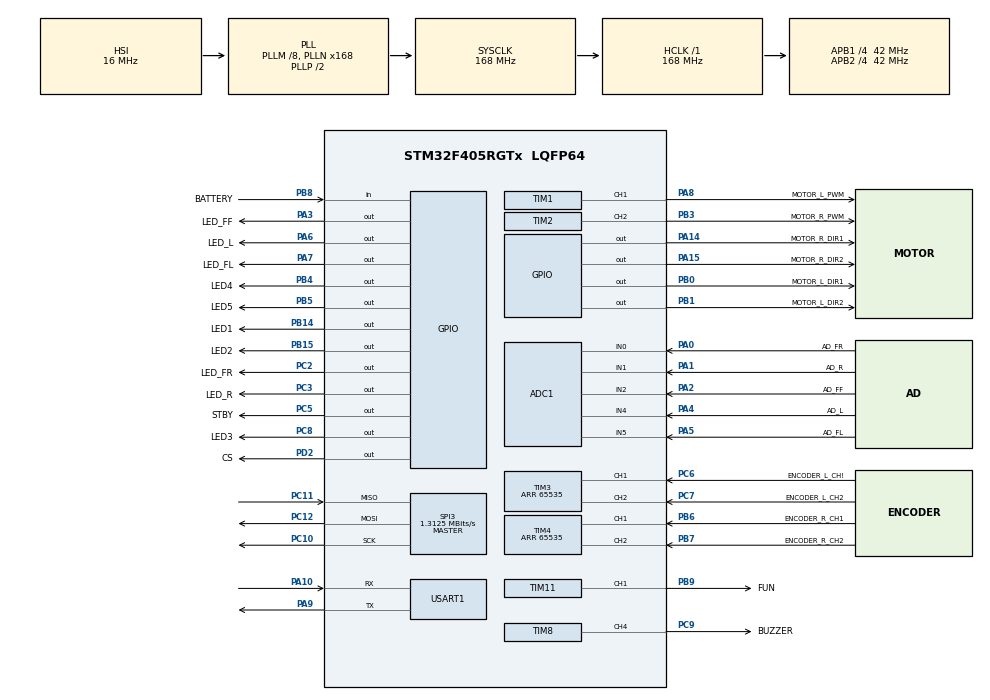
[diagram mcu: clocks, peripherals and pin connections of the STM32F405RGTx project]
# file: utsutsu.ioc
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ADC1.Channel-0\#ChannelRegularConversion=ADC_CHANNEL_0
ADC1.ContinuousConvMode=DISABLE
ADC1.DMAContinuousRequests=DISABLE
ADC1.DiscontinuousConvMode=DISABLE
ADC1.InjNumberOfConversion=0
ADC1.NbrOfConversion=1
ADC1.NbrOfConversionFlag=1
ADC1.Rank-0\#ChannelRegularConversion=1
ADC1.SamplingTime-0\#ChannelRegularConversion=ADC_SAMPLETIME_3CYCLES
ADC1.master=1
Mcu.Family=STM32F4
Mcu.Name=STM32F405RGTx
Mcu.Package=LQFP64
NVIC.PriorityGroup=NVIC_PRIORITYGROUP_4
NVIC.TIM1_BRK_TIM9_IRQn=true\:1\:0\:true\:false\:true\:true\:true
NVIC.TIM2_IRQn=true\:2\:0\:true\:false\:true\:true\:true
NVIC.TIM6_DAC_IRQn=true\:3\:0\:true\:false\:true\:true\:true
PA0-WKUP.GPIO_Label=AD_FR
PA0-WKUP.Signal=ADCx_IN0
PA1.GPIO_Label=AD_R
PA1.Signal=ADCx_IN1
PA10.Mode=Asynchronous
PA10.Signal=USART1_RX
PA14.GPIO_Label=MOTOR_R_DIR1
PA14.Signal=GPIO_Output
PA15.GPIO_Label=MOTOR_R_DIR2
PA15.Signal=GPIO_Output
PA2.GPIO_Label=AD_FF
PA2.Signal=ADCx_IN2
PA3.GPIO_Label=LED_FF
PA3.Signal=GPIO_Output
PA4.GPIO_Label=AD_L
PA4.Signal=ADCx_IN4
PA5.GPIO_Label=AD_FL
PA5.Signal=ADCx_IN5
PA6.GPIO_Label=LED_L
PA6.Signal=GPIO_Output
PA7.GPIO_Label=LED_FL
PA7.Signal=GPIO_Output
PA8.GPIO_Label=MOTOR_L_PWM
PA8.Signal=S_TIM1_CH1
PA9.Mode=Asynchronous
PA9.Signal=USART1_TX
PB0.GPIO_Label=MOTOR_L_DIR1
PB0.Signal=GPIO_Output
PB1.GPIO_Label=MOTOR_L_DIR2
PB1.Signal=GPIO_Output
PB14.GPIO_Label=LED1
PB14.Signal=GPIO_Output
PB15.GPIO_Label=LED2
PB15.Signal=GPIO_Output
PB3.GPIO_Label=MOTOR_R_PWM
PB3.Signal=S_TIM2_CH2
PB4.GPIO_Label=LED4
PB4.Signal=GPIO_Output
PB5.GPIO_Label=LED5
PB5.Signal=GPIO_Output
PB6.GPIO_Label=ENCODER_R_CH1
PB6.Signal=S_TIM4_CH1
PB7.GPIO_Label=ENCODER_R_CH2
PB7.Signal=S_TIM4_CH2
PB8.GPIO_Label=BATTERY
PB8.GPIO_PuPd=GPIO_PULLUP
PB8.Signal=GPIO_Input
PB9.GPIO_Label=FUN
PB9.Signal=S_TIM11_CH1
PC10.Mode=Full_Duplex_Master
PC10.Signal=SPI3_SCK
PC11.Mode=Full_Duplex_Master
PC11.Signal=SPI3_MISO
PC12.Mode=Full_Duplex_Master
PC12.Signal=SPI3_MOSI
PC2.GPIO_Label=LED_FR
PC2.Signal=GPIO_Output
PC3.GPIO_Label=LED_R
PC3.Signal=GPIO_Output
PC5.GPIO_Label=STBY
PC5.Signal=GPIO_Output
PC6.GPIO_Label=ENCODER_L_CH\!
PC6.Signal=S_TIM3_CH1
PC7.GPIO_Label=ENCODER_L_CH2
PC7.Signal=S_TIM3_CH2
PC8.GPIO_Label=LED3
PC8.Signal=GPIO_Output
PC9.GPIO_Label=BUZZER
PC9.Signal=S_TIM8_CH4
PD2.GPIO_Label=CS
PD2.Signal=GPIO_Output
ProjectManager.HeapSize=0x200
ProjectManager.StackSize=0x400
ProjectManager.TargetToolchain=STM32CubeIDE
RCC.48MHZClocksFreq_Value=84000000
RCC.AHBFreq_Value=168000000
RCC.APB1CLKDivider=RCC_HCLK_DIV4
RCC.APB1Freq_Value=42000000
RCC.APB1TimFreq_Value=84000000
RCC.APB2CLKDivider=RCC_HCLK_DIV4
RCC.APB2Freq_Value=42000000
RCC.APB2TimFreq_Value=84000000
RCC.CortexFreq_Value=168000000
RCC.HCLKFreq_Value=168000000
RCC.HSE_VALUE=25000000
RCC.HSI_VALUE=16000000
RCC.LSE_VALUE=32768
RCC.PLLM=8
RCC.PLLN=168
RCC.SYSCLKFreq_VALUE=168000000
RCC.SYSCLKSource=RCC_SYSCLKSOURCE_PLLCLK
RCC.VCOOutputFreq_Value=336000000
SH.ADCx_IN0.0=ADC1_IN0,IN0
SH.ADCx_IN1.0=ADC1_IN1,IN1
SH.ADCx_IN2.0=ADC1_IN2,IN2
SH.ADCx_IN4.0=ADC1_IN4,IN4
SH.ADCx_IN5.0=ADC1_IN5,IN5
SH.S_TIM11_CH1.0=TIM11_CH1,PWM Generation1 CH1
SH.S_TIM1_CH1.0=TIM1_CH1,PWM Generation1 CH1
SH.S_TIM2_CH2.0=TIM2_CH2,PWM Generation2 CH2
SH.S_TIM3_CH1.0=TIM3_CH1,Encoder_Interface
SH.S_TIM3_CH2.0=TIM3_CH2,Encoder_Interface
SH.S_TIM4_CH1.0=TIM4_CH1,Encoder_Interface
SH.S_TIM4_CH2.0=TIM4_CH2,Encoder_Interface
SH.S_TIM8_CH4.0=TIM8_CH4,PWM Generation4 CH4
SPI3.BaudRatePrescaler=SPI_BAUDRATEPRESCALER_32
SPI3.CLKPhase=SPI_PHASE_2EDGE
SPI3.CLKPolarity=SPI_POLARITY_HIGH
SPI3.CalculateBaudRate=1.3125 MBits/s
SPI3.Direction=SPI_DIRECTION_2LINES
SPI3.Mode=SPI_MODE_MASTER
SPI3.VirtualType=VM_MASTER
TIM1.Channel-PWM\ Generation1\ CH1=TIM_CHANNEL_1
TIM1.OCPolarity_1=TIM_OCPOLARITY_HIGH
TIM1.Period=1000
TIM1.Pulse-PWM\ Generation1\ CH1=500
TIM11.Channel=TIM_CHANNEL_1
TIM11.Period=1000
TIM2.Channel-PWM\ Generation2\ CH2=TIM_CHANNEL_2
TIM2.OCMode_PWM-PWM\ Generation2\ CH2=TIM_OCMODE_PWM1
TIM2.OCPolarity_2=TIM_OCPOLARITY_HIGH
TIM2.Period=1000
TIM2.Pulse-PWM\ Generation2\ CH2=500
TIM3.EncoderMode=TIM_ENCODERMODE_TI12
TIM3.Period=65535
TIM4.EncoderMode=TIM_ENCODERMODE_TI12
TIM4.Period=65535
TIM6.AutoReloadPreload=TIM_AUTORELOAD_PRELOAD_DISABLE
TIM6.Period=250-1
TIM6.Prescaler=84-1
TIM8.Channel-PWM\ Generation4\ CH4=TIM_CHANNEL_4
TIM8.Period=1000-1
TIM8.Prescaler=84-1
TIM8.Pulse-PWM\ Generation4\ CH4=50
USART1.VirtualMode=VM_ASYNC
VP_TIM11_VS_ClockSourceINT.Mode=Enable_Timer
VP_TIM1_VS_ClockSourceINT.Mode=Internal
VP_TIM2_VS_ClockSourceINT.Mode=Internal
VP_TIM6_VS_ClockSourceINT.Mode=Enable_Timer
board=custom

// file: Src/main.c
/* USER CODE BEGIN Header */
/**
  ******************************************************************************
  * @file           : main.c
  * @brief          : Main program body
  ******************************************************************************
  * @attention
  *
  * <h2><center>&copy; Copyright (c) 2019 STMicroelectronics.
  * All rights reserved.</center></h2>
  *
  * This software component is licensed by ST under BSD 3-Clause license,
  * the "License"; You may not use this file except in compliance with the
  * License. You may obtain a copy of the License at:
  *                        opensource.org/licenses/BSD-3-Clause
  *
  ******************************************************************************
  */
/* USER CODE END Header */

#include "main.h"
#include "adc.h"
#include "spi.h"
#include "tim.h"
#include "usart.h"
#include "gpio.h"

/* USER CODE BEGIN Includes */
#define MAIN_C_
#include <Mouse/global.h>
/* USER CODE END Includes */

void SystemClock_Config(void);

/* USER CODE BEGIN 0 */
int __io_putchar(int c) {
  if( c == '\n' ) {
    int _c = '\r';
    HAL_UART_Transmit(&huart1, &_c, 1, 1);
  }
  HAL_UART_Transmit(&huart1, &c, 1, 1);
  return 0;
}
/* USER CODE END 0 */

int main(void)
{

  /* MCU Configuration--------------------------------------------------------*/

  /* Reset of all peripherals, Initializes the Flash interface and the Systick. */
  HAL_Init();

  /* Configure the system clock */
  SystemClock_Config();

  /* Initialize all configured peripherals */
  MX_GPIO_Init();
  MX_USART1_UART_Init();
  MX_SPI3_Init();
  MX_ADC1_Init();
  MX_TIM1_Init();
  MX_TIM2_Init();
  MX_TIM3_Init();
  MX_TIM4_Init();
  MX_TIM6_Init();
  MX_TIM8_Init();
  MX_TIM11_Init();
  /* USER CODE BEGIN 2 */
  setbuf(stdout,NULL);
  HAL_Delay(1);

  UtsutsuSystem();

  /* USER CODE END 2 */

  /* Infinite loop */
  while (1)
  {

  }
}

void SystemClock_Config(void)
{
  RCC_OscInitTypeDef RCC_OscInitStruct = {0};
  RCC_ClkInitTypeDef RCC_ClkInitStruct = {0};

  /** Configure the main internal regulator output voltage
  */
  __HAL_RCC_PWR_CLK_ENABLE();
  __HAL_PWR_VOLTAGESCALING_CONFIG(PWR_REGULATOR_VOLTAGE_SCALE1);
  /** Initializes the CPU, AHB and APB busses clocks
  */
  RCC_OscInitStruct.OscillatorType = RCC_OSCILLATORTYPE_HSI;
  RCC_OscInitStruct.HSIState = RCC_HSI_ON;
  RCC_OscInitStruct.HSICalibrationValue = RCC_HSICALIBRATION_DEFAULT;
  RCC_OscInitStruct.PLL.PLLState = RCC_PLL_ON;
  RCC_OscInitStruct.PLL.PLLSource = RCC_PLLSOURCE_HSI;
  RCC_OscInitStruct.PLL.PLLM = 8;
  RCC_OscInitStruct.PLL.PLLN = 168;
  RCC_OscInitStruct.PLL.PLLP = RCC_PLLP_DIV2;
  RCC_OscInitStruct.PLL.PLLQ = 4;
  if (HAL_RCC_OscConfig(&RCC_OscInitStruct) != HAL_OK)
  {
    Error_Handler();
  }
  /** Initializes the CPU, AHB and APB busses clocks
  */
  RCC_ClkInitStruct.ClockType = RCC_CLOCKTYPE_HCLK|RCC_CLOCKTYPE_SYSCLK
                              |RCC_CLOCKTYPE_PCLK1|RCC_CLOCKTYPE_PCLK2;
  RCC_ClkInitStruct.SYSCLKSource = RCC_SYSCLKSOURCE_PLLCLK;
  RCC_ClkInitStruct.AHBCLKDivider = RCC_SYSCLK_DIV1;
  RCC_ClkInitStruct.APB1CLKDivider = RCC_HCLK_DIV4;
  RCC_ClkInitStruct.APB2CLKDivider = RCC_HCLK_DIV4;

  if (HAL_RCC_ClockConfig(&RCC_ClkInitStruct, FLASH_LATENCY_5) != HAL_OK)
  {
    Error_Handler();
  }
}

void Error_Handler(void)
{
}

/************************ (C) COPYRIGHT STMicroelectronics *****END OF FILE****/
